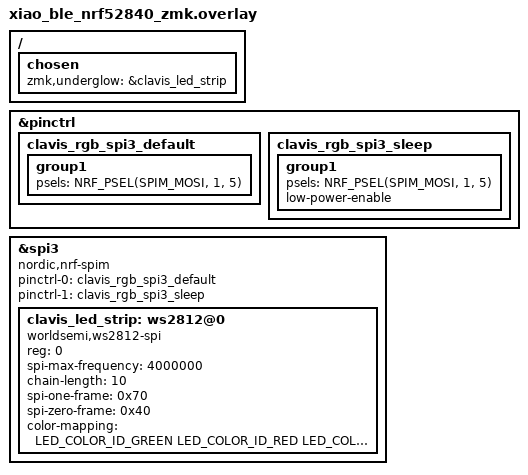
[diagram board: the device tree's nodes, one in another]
#include <zephyr/dt-bindings/pinctrl/nrf-pinctrl.h>
#include <dt-bindings/led/led.h>

/ {
    chosen {
        zmk,underglow = &clavis_led_strip;
    };
};

&pinctrl {
    clavis_rgb_spi3_default: clavis_rgb_spi3_default {
        group1 {
            /* REV 1: D18 / P1.05. REV 2 changes only this to (0, 4). */
            psels = <NRF_PSEL(SPIM_MOSI, 1, 5)>;
        };
    };

    clavis_rgb_spi3_sleep: clavis_rgb_spi3_sleep {
        group1 {
            psels = <NRF_PSEL(SPIM_MOSI, 1, 5)>;
            low-power-enable;
        };
    };
};

&spi3 {
    compatible = "nordic,nrf-spim";
    status = "okay";

    pinctrl-0 = <&clavis_rgb_spi3_default>;
    pinctrl-1 = <&clavis_rgb_spi3_sleep>;
    pinctrl-names = "default", "sleep";

    clavis_led_strip: ws2812@0 {
        compatible = "worldsemi,ws2812-spi";
        reg = <0>;
        spi-max-frequency = <4000000>;
        chain-length = <10>;
        spi-one-frame = <0x70>;
        spi-zero-frame = <0x40>;

        color-mapping = <
            LED_COLOR_ID_GREEN
            LED_COLOR_ID_RED
            LED_COLOR_ID_BLUE
        >;
    };
};
